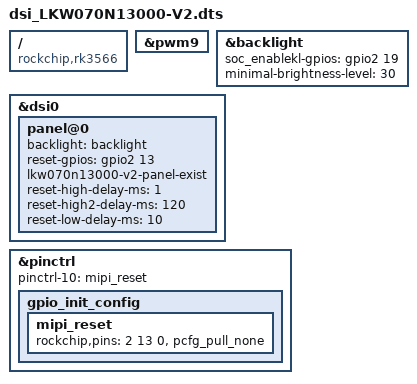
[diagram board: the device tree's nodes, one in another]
/dts-v1/;
/plugin/;
/ {
	compatible = "rockchip,rk3566";

	fragment@0 {
		target = <&pwm9>;
		__overlay__ {
			status = "okay";
		};
	};
	fragment@1 {
		target = <&backlight>;
		__overlay__ {
			status = "okay";
			soc_enablekl-gpios = <&gpio2 19 0>;
			minimal-brightness-level = <30>;
		};
	};
	fragment@2 {
		target = <&dsi0>;
		__overlay__ {
			status = "okay";
			panel@0 {
				backlight = <&backlight>;
				reset-gpios = <&gpio2 13 0>;
				lkw070n13000-v2-panel-exist;
				reset-high-delay-ms = <1>;
				reset-high2-delay-ms = <120>;
				reset-low-delay-ms = <10>;
			};
		};
	};
	fragment@3 {
		target = <&pinctrl>;
		__overlay__ {
			pinctrl-10 = <&mipi_reset>;
			gpio_init_config {
				mipi_reset: mipi_reset {
					rockchip,pins =
						<2 13 0 &pcfg_pull_none>;
				};
			};
		};
	};
};
